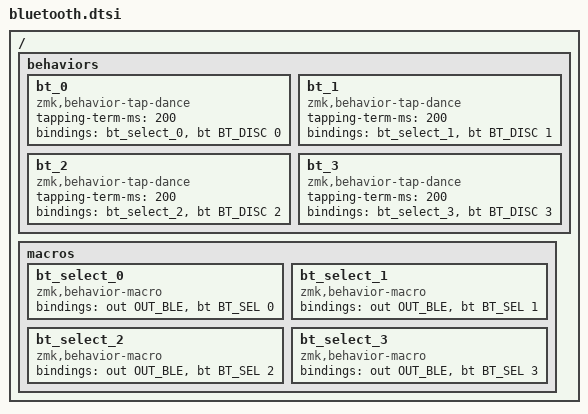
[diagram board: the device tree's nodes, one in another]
// Bluetooth behaviors and macros for advanced profile management
// Provides tap-dance behaviors for connecting/disconnecting BT profiles

/ {
    behaviors {
        // Bluetooth tap-dance behaviors
        bt_0: bt_0 {
            compatible = "zmk,behavior-tap-dance";
            #binding-cells = <0>;
            tapping-term-ms = <200>;
            bindings = <&bt_select_0>, <&bt BT_DISC 0>;
        };

        bt_1: bt_1 {
            compatible = "zmk,behavior-tap-dance";
            #binding-cells = <0>;
            tapping-term-ms = <200>;
            bindings = <&bt_select_1>, <&bt BT_DISC 1>;
        };

        bt_2: bt_2 {
            compatible = "zmk,behavior-tap-dance";
            #binding-cells = <0>;
            tapping-term-ms = <200>;
            bindings = <&bt_select_2>, <&bt BT_DISC 2>;
        };

        bt_3: bt_3 {
            compatible = "zmk,behavior-tap-dance";
            #binding-cells = <0>;
            tapping-term-ms = <200>;
            bindings = <&bt_select_3>, <&bt BT_DISC 3>;
        };
    };

    macros {
        bt_select_0: bt_select_0 {
            compatible = "zmk,behavior-macro";
            #binding-cells = <0>;
            bindings = <&out OUT_BLE>, <&bt BT_SEL 0>;
        };

        bt_select_1: bt_select_1 {
            compatible = "zmk,behavior-macro";
            #binding-cells = <0>;
            bindings = <&out OUT_BLE>, <&bt BT_SEL 1>;
        };

        bt_select_2: bt_select_2 {
            compatible = "zmk,behavior-macro";
            #binding-cells = <0>;
            bindings = <&out OUT_BLE>, <&bt BT_SEL 2>;
        };

        bt_select_3: bt_select_3 {
            compatible = "zmk,behavior-macro";
            #binding-cells = <0>;
            bindings = <&out OUT_BLE>, <&bt BT_SEL 3>;
        };
    };
};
